VERSION ""

NS_ :

BS_:

BU_: GateWay EMS EPB TCU

BO_ 320 EMS_WheelSpd: 1 Vector__XXX
 SG_ WheelSpd : 0|8@1+ (1,0) [0|255] "km/h" Vector__XXX

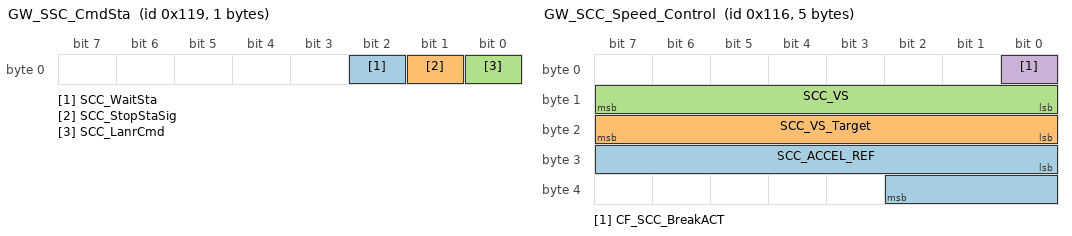
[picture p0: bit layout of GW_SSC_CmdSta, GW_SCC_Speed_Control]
BO_ 281 GW_SSC_CmdSta: 1 GateWay
 SG_ SCC_WaitSta : 2|1@1+ (1,0) [0|1] "" Vector__XXX
 SG_ SCC_StopStaSig : 1|1@1+ (1,0) [0|1] "" Vector__XXX
 SG_ SCC_LanrCmd : 0|1@1+ (1,0) [0|1] "" Vector__XXX

BO_ 304 GW_BCM_WheelSpd_FL: 1 GateWay
 SG_ WheelSpd_FL : 0|8@1+ (1,0) [0|255] "km/h" Vector__XXX

BO_ 85 EMS_NM_Flag: 1 EMS
 SG_ EMS_Flag : 0|1@1+ (1,1) [0|1] ""  GateWay

BO_ 84 EPB_NM_Flag: 1 EPB
 SG_ EPB_Flag : 0|1@1+ (1,1) [0|1] ""  GateWay

BO_ 83 TCU_NM_Flag: 1 TCU
 SG_ TCU_Flag : 0|1@1+ (1,1) [0|1] ""  GateWay

BO_ 69 GW_NM_EMS: 1 GateWay
 SG_ NmSleepCmd_EMS : 0|1@1+ (1,0) [0|1] ""  EMS

BO_ 68 GW_NM_EPB: 1 GateWay
 SG_ NmSleepCmd_EPB : 0|1@1+ (1,0) [0|1] ""  EPB

BO_ 67 GW_NM_TCU: 1 GateWay
 SG_ NmSleepCmd_TCU : 0|1@1+ (1,0) [0|1] ""  TCU

BO_ 49 VCU_IGN1: 1 GateWay
 SG_ IGN_State : 0|1@1+ (1,0) [0|1] ""  TCU

BO_ 278 GW_SCC_Speed_Control: 5 GateWay
 SG_ SCC_ACCEL_REF : 24|11@1+ (0.01,-10.23) [-10.23|10.24] "m/s^2"  TCU,EMS
 SG_ SCC_VS_Target : 16|8@1+ (1,0) [0|255] "km/h"  EMS
 SG_ SCC_VS : 8|8@1+ (1,0) [0|255] "km/h"  EMS
 SG_ CF_SCC_BreakACT : 0|1@1+ (1,0) [0|1] ""  TCU,EPB

BO_ 277 GW_SCC_E_stop: 1 GateWay
 SG_ CF_Estop : 0|1@1+ (1,0) [0|1] ""  TCU,EPB

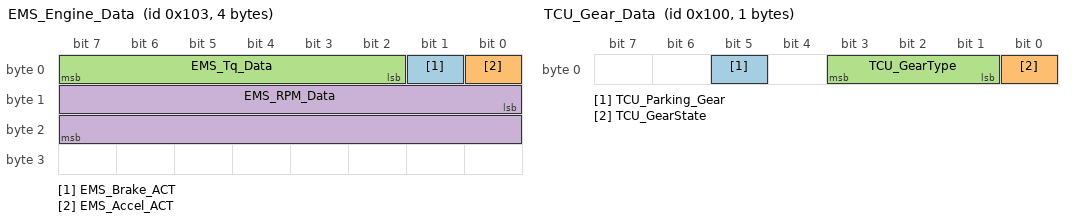
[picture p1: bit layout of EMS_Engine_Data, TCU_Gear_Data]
BO_ 259 EMS_Engine_Data: 4 EMS
 SG_ EMS_Brake_ACT : 1|1@1+ (1,0) [0|1] ""  GateWay,TCU,EPB
 SG_ EMS_Accel_ACT : 0|1@1+ (1,0) [0|1] ""  GateWay,TCU
 SG_ EMS_Tq_Data : 2|6@1+ (10,0) [0|630] "Nm"  GateWay,TCU
 SG_ EMS_RPM_Data : 8|16@1+ (0.25,1) [0|16383.75] "rpm"  TCU,GateWay

BO_ 258 EPB_Press_Data: 2 EPB
 SG_ EPB_CylinderPress : 1|12@1+ (0.1,0) [0|409.5] "Bar"  GateWay
 SG_ EPB_CylinderState : 0|1@1+ (1,0) [0|1] ""  GateWay

BO_ 257 EPB_State_Data: 1 EPB
 SG_ EPB_ACT : 1|1@1+ (1,0) [0|1] ""  GateWay
 SG_ EPB_State : 0|1@1+ (1,0) [0|1] ""  GateWay

BO_ 256 TCU_Gear_Data: 1 TCU
 SG_ TCU_Parking_Gear : 5|1@1+ (1,0) [0|1] ""  GateWay
 SG_ TCU_GearState : 0|1@1+ (1,0) [0|1] ""  GateWay
 SG_ TCU_GearType : 1|3@1+ (1,0) [0|7] ""  GateWay

BA_DEF_  "BusType" STRING ;
BA_DEF_DEF_  "BusType" "CAN";
